# S6E2CC register map
File version: 1.1
CPU: 
Registers are 8-bit, read-write, reset 0x0 unless marked. A register's access mark holds for its fields unless they carry their own. Offsets are from the block's base; [hi:lo] are bit positions; {n}, {i} and the like mark numbered series.

## DMAC — DMAC Registers
Base 0x40060000
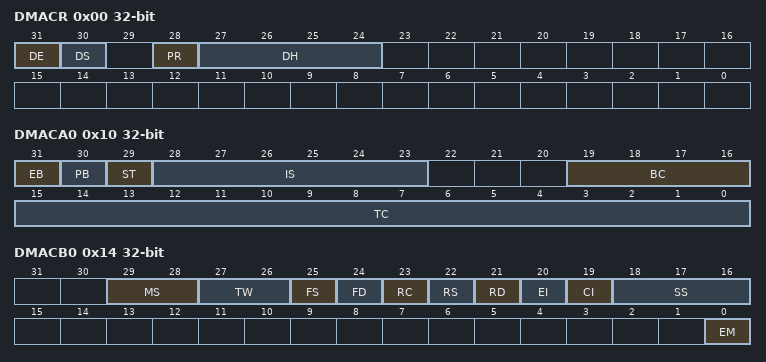
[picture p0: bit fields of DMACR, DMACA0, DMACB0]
0x00 DMACR 32-bit — Entire DMAC Configuration Register
  [31] DE — DMA Enable (all-channel operation enable bit)
  [30] DS — DMA Stop
  [28] PR — Priority Rotation
  [27:24] DH — DMA Halt (All-channel pause bit)
0x10 DMACA0 32-bit — Configuration A Register
  [31] EB — Enable bit (individual-channel operation enable bit)
  [30] PB — Pause bit (individual-channel pause bit)
  [29] ST — Software Trigger
  [28:23] IS — Input Select
  [19:16] BC — Block Count
  [15:0] TC — Transfer Count
0x14 DMACB0 32-bit — Configuration B Register
  [29:28] MS — Mode Select
  [27:26] TW — Transfer Width
  [25] FS — Fixed Source
  [24] FD — Fixed Destination
  [23] RC — Reload Count (BC/TC reload)
  [22] RS — Reload Source
  [21] RD — Reload Destination
  [20] EI — Error Interrupt (unsuccessful transfer completion interrupt enable)
  [19] CI — Completion Interrupt (successful transfer completion interrupt enable)
  [18:16] SS — Stop Status (stop status notification)
  [0] EM — Enable bit Mask (EB bit clear mask)
0x18 DMACSA0 32-bit — Transfer Source Address Register
0x1C DMACDA0 32-bit — Transfer Destination Address Register
{0x10+0x10*i} DMACA{i} 32-bit reset not defined (i=1..7) — Configuration A Register {i}
{0x14+0x10*i} DMACB{i} 32-bit reset not defined (i=1..7) — Configuration B Register {i}
{0x18+0x10*i} DMACSA{i} 32-bit reset not defined (i=1..7) — Transfer Source Address Register {i}
{0x1C+0x10*i} DMACDA{i} 32-bit reset not defined (i=1..7) — Transfer Destination Address Register {i}

## DSTC — DSTC registers
Base 0x40061000
0x00 DESTP 32-bit — Descriptor top address Register
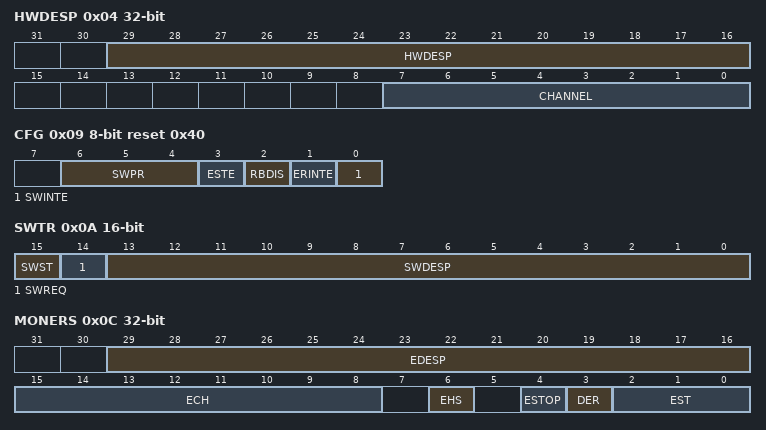
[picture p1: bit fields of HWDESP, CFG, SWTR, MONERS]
0x04 HWDESP 32-bit — Hardware DES pointer Register
  [29:16] HWDESP, [7:0] CHANNEL
0x08 CMD reset 0x1 — Command Register
0x09 CFG reset 0x40 — Configuration Register
  [6:4] SWPR — Software transfer priority
  [3] ESTE — Error stop enable
  [2] RBDIS — Read skip buffer disable
  [1] ERINTE — Error interrupt enable
  [0] SWINTE — Software interrupt enable
0x0A SWTR 16-bit — Software trigger Register
  [15] SWST ro — Software status
  [14] SWREQ ro — Software request
  [13:0] SWDESP — Software DES pointer
0x0C MONERS 32-bit
  [29:16] EDESP ro — Error DES pointer
  [15:8] ECH ro — Error hardware channel
  [6] EHS ro — Error hardware software
  [4] ESTOP ro — Error stop
  [3] DER ro — Double error
  [2:0] EST ro — Error status
0x10 DREQENB0 32-bit — DMA request enable Register 0
{0x10+4i} DREQENB{i} 32-bit reset not defined (i=1..7) — DMA request enable Register {i}
0x30 HWINT0 32-bit — Hardware transfer interrupt Register 0
{0x30+4i} HWINT{i} 32-bit reset not defined (i=1..7) — Hardware transfer interrupt Register {i}
0x50 HWINTCLR0 32-bit — Hardware transfer interrupt clear Register 0
{0x50+4i} HWINTCLR{i} 32-bit reset not defined (i=1..7) — Hardware transfer interrupt clear Register {i}
0x70 DQMSK0 32-bit — DMA request mask Register 0
{0x70+4i} DQMSK{i} 32-bit reset not defined (i=1..7) — DMA request mask Register {i}
0x90 DQMSKCLR0 32-bit — DMA request mask clear Register 0
{0x90+4i} DQMSKCLR{i} 32-bit reset not defined (i=1..7) — DMA request mask clear Register {i}

## CANPRES — CAN Prescaler Register
Base 0x40037000
0x00 CANPRE reset 0xB — CAN Prescaler Register
  [3:0] CANPRE — CAN prescaler setting bits

## ETHERNET_CONTROL — Ethernet system control
Base 0x40066000
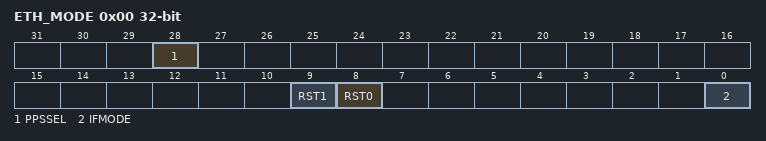
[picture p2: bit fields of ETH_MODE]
0x00 ETH_MODE 32-bit — Mode Select Register
  [28] PPSSEL — Select either of the system time counter pulse outputs of the Ethernet-MAC PTP function to output to E_PPS0_PPS1 pin
  [9] RST1 — reset signal against Ethernet-MAC (ch.1)
  [8] RST0 — reset signal against Ethernet-MAC (ch.0)
  [0] IFMODE — Mode selector
0x08 ETH_CLKG 32-bit — Clock Gating Register
  [1:0] MACEN — Select the system clock supply to Ethernet-MAC

## I2SPRE — I2S Clock Generation
Base 0x4003D000
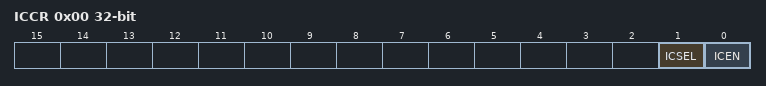
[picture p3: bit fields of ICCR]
0x00 ICCR 32-bit — I2S Clock Control Register
  [1] ICSEL — I2S clock selection bit
  [0] ICEN — I2S clock output enable bit
0x04 IPCR1 32-bit — I2S-PLL Control Register 1
  [0] IPLLEN — I2S-PLL oscillation enable bit
0x08 IPCR2 32-bit — I2S-PLL Control Register 2
  [2:0] IPOWT — I2S-PLL oscillation stabilization wait time setting bits
0x0C IPCR3 32-bit reset 0x1 — I2S-PLL Control Register 3
  [4:0] IPLLK — Frequency division ratio (K) setting bits of the I2S-PLL clock
0x10 IPCR4 32-bit reset 0x1F — I2S-PLL Control Register 4
  [6:0] IPLLN — Frequency division ratio (N) setting bits of the I2S-PLL clock
0x14 IP_STR 32-bit — I2S-PLL Status Register
  [0] IPRDY ro — I2S-PLL oscillation stabilization bit
0x18 IPINT_ENR 32-bit — I2S-PLL Interrupt Factor Enable Register
  [0] IPCSE — I2S-PLL oscillation stabilization wait complete interrupt enable bit
0x1C IPINT_CLR 32-bit — I2S-PLL Interrupt Factor Status Register
  [0] IPCSC wo — I2S-PLL interrupt factor status bit
0x20 IPINT_STR 32-bit — I2S-PLL Interrupt Factor Clear Register
  [0] IPCSI ro — I2S-PLL oscillation stabilization interrupt factor clear bit
0x24 IPCR5 32-bit reset 0x18 — I2S-PLL Control Register 5
  [6:0] IPLLM — Frequency division ratio (M) setting bits of the I2S-PLL clock

## SDIF — SD Card Interface
Base 0x4006E000
0x00 DUMMY 32-bit reset not defined

## PCRC — 0
Base 0x40080000
0x00 PRGCRC_POLY 32-bit reset 0x4C11DB7 — CRC Computing Generator Polynomial Register
0x04 PRGCRC_SEED 32-bit reset 0xFFFFFFFF — CRC Computing Initial Value Register
0x08 PRGCRC_FXOR 32-bit reset 0xFFFFFFFF — CRC Computing Resault XOR Value Register
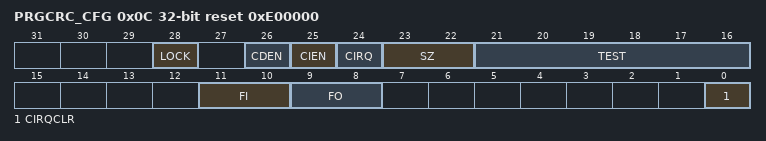
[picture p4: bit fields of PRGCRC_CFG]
0x0C PRGCRC_CFG 32-bit reset 0xE00000 — CRC Computing Configuration Register
  [28] LOCK ro
  [26] CDEN — DMA request enable
  [25] CIEN — Interrupt request enable
  [24] CIRQ ro — Interrupt request
  [23:22] SZ — Input data size
  [21:16] TEST
  [11:10] FI — Input data format
  [9:8] FO — output data format
  [0] CIRQCLR wo — Interrupt request clear
0x10 PRGCRC_WR 32-bit — CRC Computing Input Data Register
0x14 PRGCRC_RD 32-bit — CRC Computing Output Data Register
